# M036 register map
File version: 2.0.2.1
Registers are 32-bit, read-write, reset 0x0 unless marked. A register's access mark holds for its fields unless they carry their own. Offsets are from the block's base; [hi:lo] are bit positions; {n}, {i} and the like mark numbered series.

## PG — Port G
Base 0x400C0600
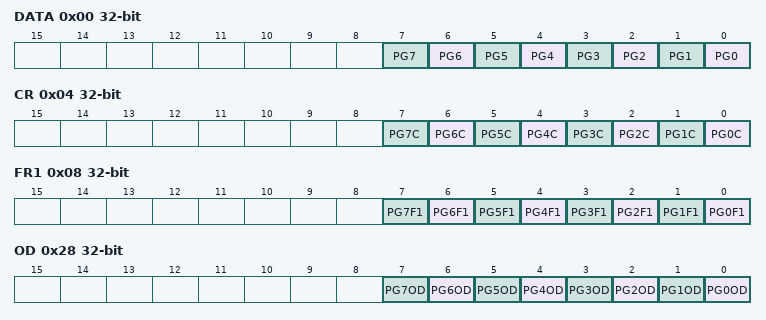
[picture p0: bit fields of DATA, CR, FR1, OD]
0x00 DATA — PG Data Register
  [n] PG{n} (n=0..7)
0x04 CR — PG Control Register
  [n] PG{n}C (n=0..7)
0x08 FR1 — PG Function Register 1
  [n] PG{n}F1 (n=0..7)
0x28 OD — PG Open Drain Control Register
  [n] PG{n}OD (n=0..7)
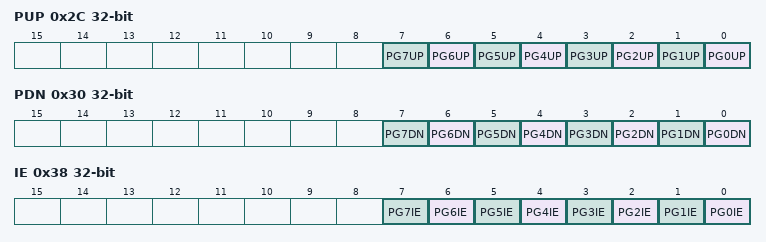
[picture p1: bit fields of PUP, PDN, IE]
0x2C PUP — PG Pull-up Control Register
  [n] PG{n}UP (n=0..7)
0x30 PDN — PG Pull-Down Control Register
  [n] PG{n}DN (n=0..7)
0x38 IE — PG Input Enable Control Register
  [n] PG{n}IE (n=0..7)

## PH — Port H
Base 0x400C0700
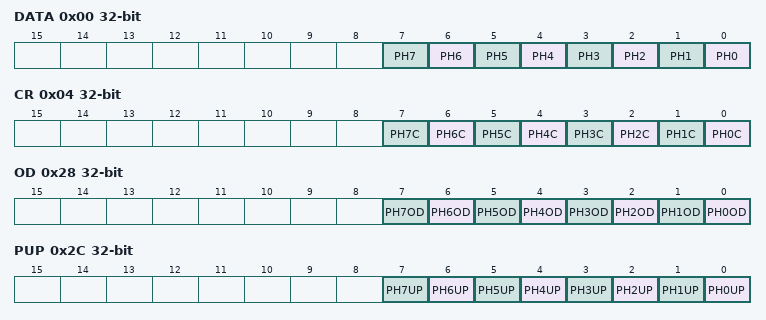
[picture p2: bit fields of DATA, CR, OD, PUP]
0x00 DATA — PH Data Register
  [n] PH{n} (n=0..7)
0x04 CR — PH Control Register
  [n] PH{n}C (n=0..7)
0x28 OD — PH Open Drain Control Register
  [n] PH{n}OD (n=0..7)
0x2C PUP — PH Pull-up Control Register
  [n] PH{n}UP (n=0..7)
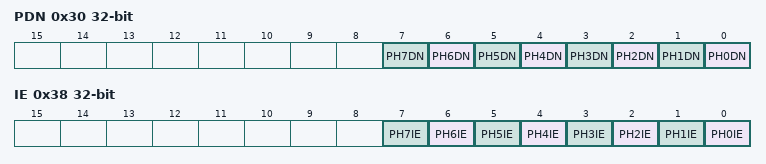
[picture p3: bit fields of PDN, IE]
0x30 PDN — PH Pull-Down Control Register
  [n] PH{n}DN (n=0..7)
0x38 IE — PH Input Enable Control Register
  [n] PH{n}IE (n=0..7)

## PJ — Port J
Base 0x400C0800
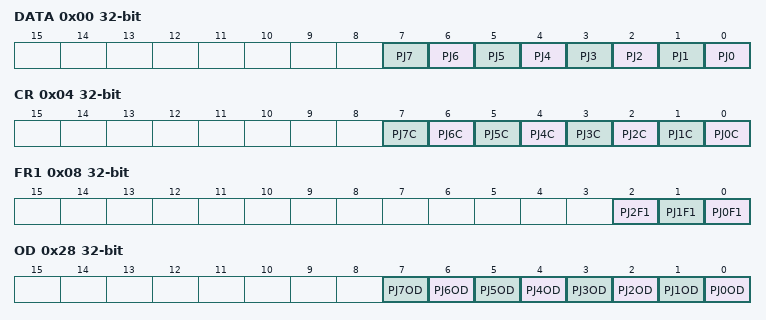
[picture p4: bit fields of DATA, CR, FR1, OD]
0x00 DATA — PJ Data Register
  [n] PJ{n} (n=0..7)
0x04 CR — PJ Control Register
  [n] PJ{n}C (n=0..7)
0x08 FR1 — PJ Function Register 1
  [2] PJ2F1, [1] PJ1F1, [0] PJ0F1
0x28 OD — PJ Open Drain Control Register
  [n] PJ{n}OD (n=0..7)
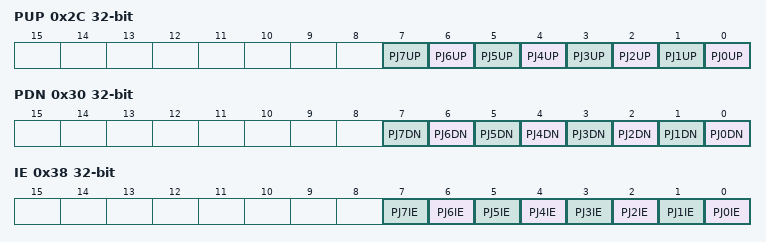
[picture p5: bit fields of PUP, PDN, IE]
0x2C PUP — PJ Pull-up Control Register
  [n] PJ{n}UP (n=0..7)
0x30 PDN — PJ Pull-Down Control Register
  [n] PJ{n}DN (n=0..7)
0x38 IE — PJ Input Enable Control Register
  [n] PJ{n}IE (n=0..7)

## PK — Port K
Base 0x400C0900
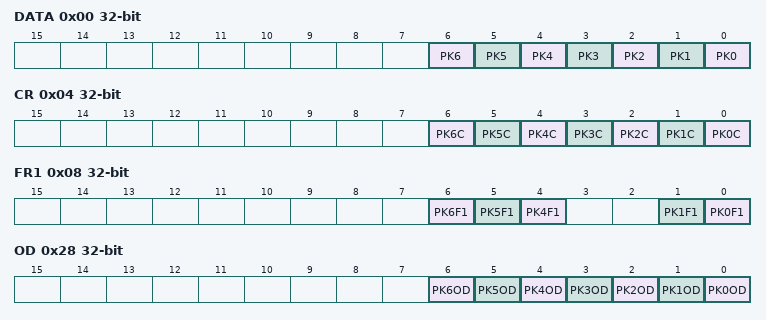
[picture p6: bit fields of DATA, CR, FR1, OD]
0x00 DATA — PK Data Register
  [n] PK{n} (n=0..6)
0x04 CR — PK Control Register
  [n] PK{n}C (n=0..6)
0x08 FR1 — PK Function Register 1
  [6] PK6F1, [5] PK5F1, [4] PK4F1, [1] PK1F1, [0] PK0F1
0x28 OD — PK Open Drain Control Register
  [n] PK{n}OD (n=0..6)
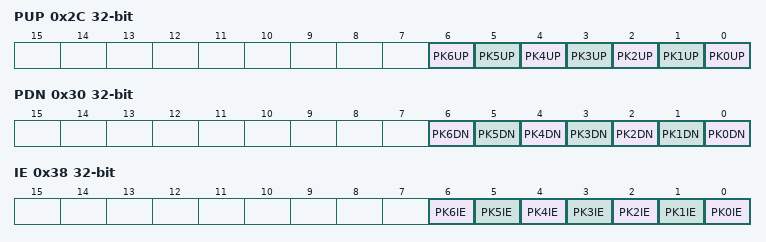
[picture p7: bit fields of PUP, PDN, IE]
0x2C PUP — PK Pull-up Control Register
  [n] PK{n}UP (n=0..6)
0x30 PDN — PK Pull-Down Control Register
  [n] PK{n}DN (n=0..6)
0x38 IE — PK Input Enable Control Register
  [n] PK{n}IE (n=0..6)

## PL — Port L
Base 0x400C0A00
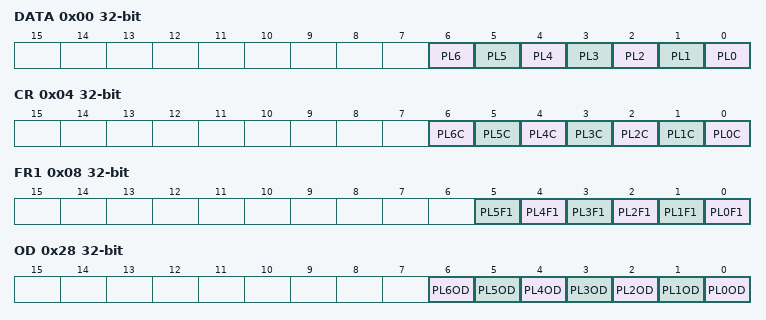
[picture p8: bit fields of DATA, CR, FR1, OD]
0x00 DATA — PL Data Register
  [n] PL{n} (n=0..6)
0x04 CR — PL Control Register
  [n] PL{n}C (n=0..6)
0x08 FR1 — PL Function Register 1
  [n] PL{n}F1 (n=0..5)
0x28 OD — PL Open Drain Control Register
  [n] PL{n}OD (n=0..6)
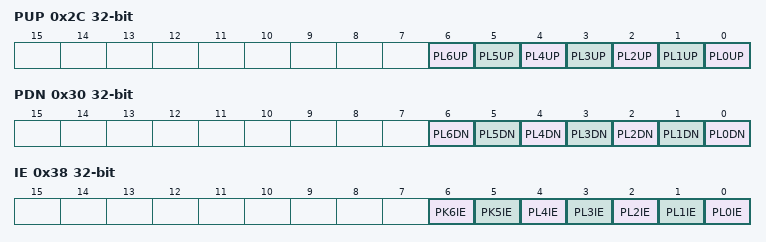
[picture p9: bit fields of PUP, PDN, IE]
0x2C PUP — PL Pull-up Control Register
  [n] PL{n}UP (n=0..6)
0x30 PDN — PL Pull-Down Control Register
  [n] PL{n}DN (n=0..6)
0x38 IE — PL Input Enable Control Register
  [6] PK6IE, [5] PK5IE, [n] PL{n}IE (n=0..4)

## PM — Port M
Base 0x400C0B00
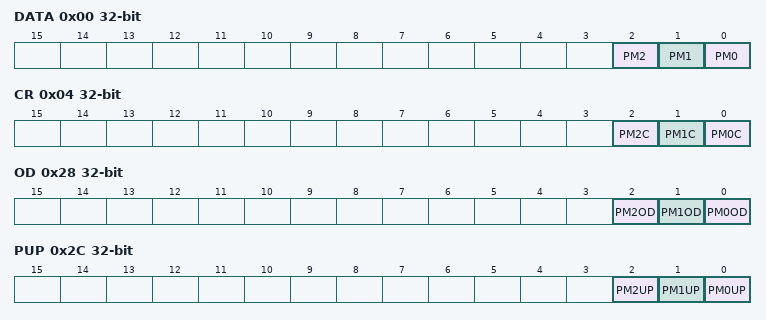
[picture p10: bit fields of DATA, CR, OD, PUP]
0x00 DATA — PM Data Register
  [2] PM2, [1] PM1, [0] PM0
0x04 CR — PM Control Register
  [2] PM2C, [1] PM1C, [0] PM0C
0x28 OD — PM Open Drain Control Register
  [2] PM2OD, [1] PM1OD, [0] PM0OD
0x2C PUP — PM Pull-up Control Register
  [2] PM2UP, [1] PM1UP, [0] PM0UP
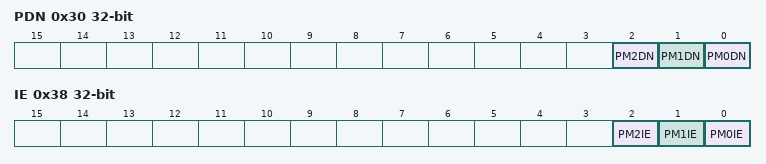
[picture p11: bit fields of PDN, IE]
0x30 PDN — PM Pull-Down Control Register
  [2] PM2DN, [1] PM1DN, [0] PM0DN
0x38 IE — PM Input Enable Control Register
  [2] PM2IE, [1] PM1IE, [0] PM0IE

## PN — Port N
Base 0x400C0C00
0x00 DATA — PN Data Register
  [0] PN0
0x04 CR — PN Control Register
  [0] PN0C
0x08 FR1 — PN Function Register 1
  [0] PN0F1
0x28 OD — PN Open Drain Control Register
  [0] PN0OD
0x2C PUP — PN Pull-up Control Register
  [0] PN0UP
0x30 PDN — PN Pull-Down Control Register
  [0] PN0DN
0x38 IE — PN Input Enable Control Register
  [0] PN0IE

## TB0 — 16-bit Timer_Event Counter (TB)
Base 0x400C4000
Same registers: TB{n} {0x400C4000+0x100*n} (n=1..9)
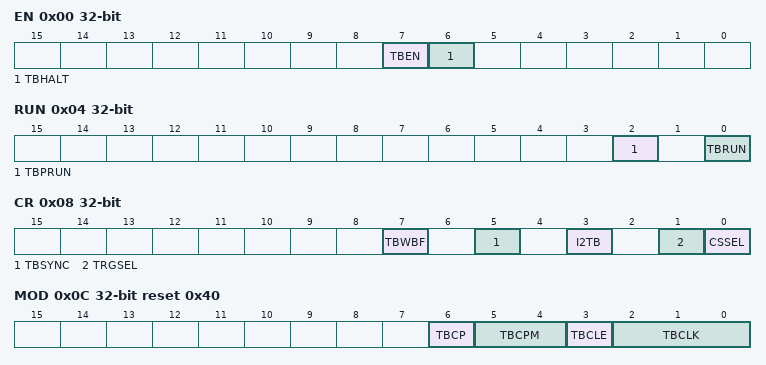
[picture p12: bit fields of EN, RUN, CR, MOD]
0x00 EN — TB Enable Register
  [7] TBEN, [6] TBHALT
0x04 RUN — TB RUN Register
  [2] TBPRUN, [0] TBRUN
0x08 CR — TB Control Register
  [7] TBWBF, [5] TBSYNC, [3] I2TB, [1] TRGSEL, [0] CSSEL
0x0C MOD reset 0x40 — TB Mode Register
  [6] TBCP wo, [5:4] TBCPM, [3] TBCLE, [2:0] TBCLK
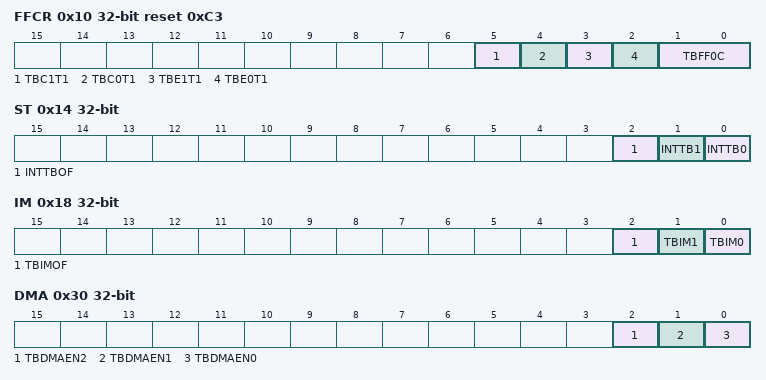
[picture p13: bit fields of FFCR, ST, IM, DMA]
0x10 FFCR reset 0xC3 — TB Flip-Flop Control Register
  [5] TBC1T1, [4] TBC0T1, [3] TBE1T1, [2] TBE0T1, [1:0] TBFF0C
0x14 ST ro — TB Status Register
  [2] INTTBOF, [1] INTTB1, [0] INTTB0
0x18 IM — TB Interrupt Mask Register
  [2] TBIMOF, [1] TBIM1, [0] TBIM0
0x1C UC ro — TB Read Capture Register
  [15:0] TBUC
0x20 RG0 — TB RG0 Timer Register
  [15:0] TBRG0
0x24 RG1 — TB RG1 Timer Register
  [15:0] TBRG1
0x28 CP0 ro (reset mask 0xFFFF0000) — TB CP0 Capture Register
  [15:0] TBCP0
0x2C CP1 ro (reset mask 0xFFFF0000) — TB CP1 Capture Register
  [15:0] TBCP1
0x30 DMA — TB DMA Enable Register
  [2] TBDMAEN2, [1] TBDMAEN1, [0] TBDMAEN0
